AUTOSAR XML (schema 00051)
package /adcm/AdaptiveApplicationSwComponentTypes
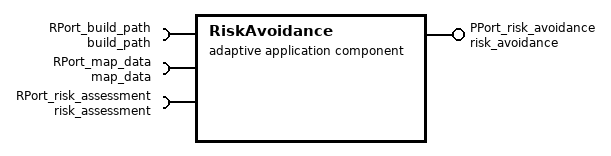
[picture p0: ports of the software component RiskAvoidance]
  adaptive application sw component type RiskAvoidance
    provide port PPort_risk_avoidance: provided-interface=risk_avoidance
    require port RPort_build_path: required-interface=build_path
    require port RPort_map_data: required-interface=map_data
    require port RPort_risk_assessment: required-interface=risk_assessment
package /adcm/Executables
  executable RiskAvoidance: category=APPLICATION_LEVEL, minimum-timer-granularity=1000
    root sw component prototype RiskAvoidance: application-type=RiskAvoidance
